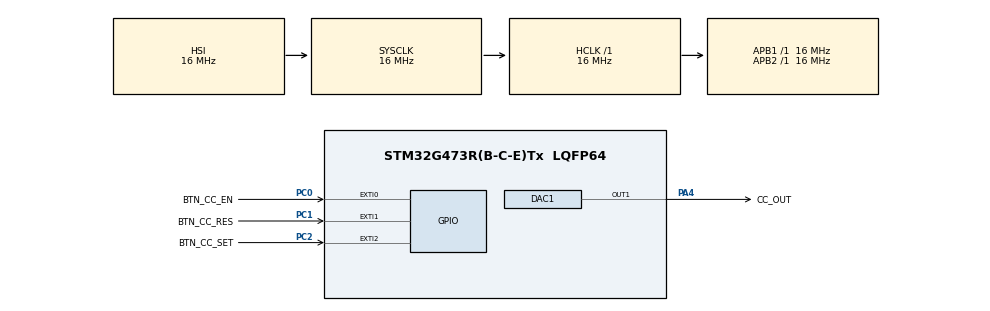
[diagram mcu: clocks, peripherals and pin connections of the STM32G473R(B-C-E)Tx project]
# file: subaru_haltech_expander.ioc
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FREERTOS.Queues01=ccStalkButtonEventQueue,10,16,1,Dynamic,NULL,NULL
FREERTOS.Tasks01=ccStalkTask,24,128,StartCCStalkTask,Default,NULL,Dynamic,NULL,NULL
FREERTOS.configUSE_NEWLIB_REENTRANT=1
Mcu.Family=STM32G4
Mcu.Name=STM32G473R(B-C-E)Tx
Mcu.Package=LQFP64
NVIC.EXTI0_IRQn=true\:5\:0\:false\:false\:true\:true\:true\:true\:true
NVIC.EXTI1_IRQn=true\:5\:0\:false\:false\:true\:true\:true\:true\:true
NVIC.EXTI2_IRQn=true\:5\:0\:false\:false\:true\:true\:true\:true\:true
NVIC.PriorityGroup=NVIC_PRIORITYGROUP_4
NVIC.TIM6_DAC_IRQn=true\:15\:0\:false\:false\:true\:false\:false\:true\:true
NVIC.TimeBase=TIM6_DAC_IRQn
NVIC.TimeBaseIP=TIM6
PA4.GPIO_Label=CC_OUT
PA4.Signal=COMP_DAC11_group
PC0.GPIO_Label=BTN_CC_EN
PC0.GPIO_PuPd=GPIO_PULLDOWN
PC0.Signal=GPXTI0
PC1.GPIO_Label=BTN_CC_RES
PC1.GPIO_PuPd=GPIO_PULLDOWN
PC1.Signal=GPXTI1
PC2.GPIO_Label=BTN_CC_SET
PC2.GPIO_PuPd=GPIO_PULLDOWN
PC2.Signal=GPXTI2
ProjectManager.HeapSize=0x200
ProjectManager.StackSize=0x400
ProjectManager.TargetToolchain=STM32CubeIDE
RCC.AHBFreq_Value=16000000
RCC.APB1Freq_Value=16000000
RCC.APB1TimFreq_Value=16000000
RCC.APB2Freq_Value=16000000
RCC.APB2TimFreq_Value=16000000
RCC.CortexFreq_Value=16000000
RCC.EXTERNAL_CLOCK_VALUE=12288000
RCC.HCLKFreq_Value=16000000
RCC.HSE_VALUE=8000000
RCC.HSI48_VALUE=48000000
RCC.HSI_VALUE=16000000
RCC.LSE_VALUE=32768
RCC.SYSCLKFreq_VALUE=16000000
RCC.USBFreq_Value=64000000
RCC.VCOOutputFreq_Value=128000000
SH.COMP_DAC11_group.0=DAC1_OUT1,DAC_OUT1
VP_FREERTOS_VS_CMSIS_V2.Mode=CMSIS_V2
VP_SYS_VS_DBSignals.Mode=DisableDeadBatterySignals
VP_SYS_VS_tim6.Mode=TIM6
board=custom

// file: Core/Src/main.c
/* USER CODE BEGIN Header */
/**
  ******************************************************************************
  * @file           : main.c
  * @brief          : Main program body
  ******************************************************************************
  * @attention
  *
  * Copyright (c) 2026 STMicroelectronics.
  * All rights reserved.
  *
  * This software is licensed under terms that can be found in the LICENSE file
  * in the root directory of this software component.
  * If no LICENSE file comes with this software, it is provided AS-IS.
  *
  ******************************************************************************
  */
/* USER CODE END Header */
#include "main.h"
#include "cmsis_os.h"

/* USER CODE BEGIN Includes */
#include "cruise_control_stalk.h"
/* USER CODE END Includes */

DAC_HandleTypeDef hdac1;

/* Definitions for ccStalkTask */
osThreadId_t ccStalkTaskHandle;
const osThreadAttr_t ccStalkTask_attributes = {
  .name = "ccStalkTask",
  .priority = (osPriority_t) osPriorityNormal,
  .stack_size = 128 * 4
};
/* Definitions for ccStalkButtonEventQueue */
osMessageQueueId_t ccStalkButtonEventQueueHandle;
const osMessageQueueAttr_t ccStalkButtonEventQueue_attributes = {
  .name = "ccStalkButtonEventQueue"
};

void SystemClock_Config(void);
static void MX_GPIO_Init(void);
static void MX_DAC1_Init(void);
void StartCCStalkTask(void *argument);

int main(void)
{

  /* MCU Configuration--------------------------------------------------------*/

  /* Reset of all peripherals, Initializes the Flash interface and the Systick. */
  HAL_Init();

  /* Configure the system clock */
  SystemClock_Config();

  /* Initialize all configured peripherals */
  MX_GPIO_Init();
  MX_DAC1_Init();

  /* Init scheduler */
  osKernelInitialize();

  /* Create the queue(s) */
  /* creation of ccStalkButtonEventQueue */
  ccStalkButtonEventQueueHandle = osMessageQueueNew (10, 16, &ccStalkButtonEventQueue_attributes);

  /* Create the thread(s) */
  /* creation of ccStalkTask */
  ccStalkTaskHandle = osThreadNew(StartCCStalkTask, NULL, &ccStalkTask_attributes);

  /* Start scheduler */
  osKernelStart();

  /* We should never get here as control is now taken by the scheduler */

  /* Infinite loop */
  while (1)
  {

  }
}

void SystemClock_Config(void)
{
  RCC_OscInitTypeDef RCC_OscInitStruct = {0};
  RCC_ClkInitTypeDef RCC_ClkInitStruct = {0};

  /** Configure the main internal regulator output voltage
  */
  HAL_PWREx_ControlVoltageScaling(PWR_REGULATOR_VOLTAGE_SCALE1);

  /** Initializes the RCC Oscillators according to the specified parameters
  * in the RCC_OscInitTypeDef structure.
  */
  RCC_OscInitStruct.OscillatorType = RCC_OSCILLATORTYPE_HSI;
  RCC_OscInitStruct.HSIState = RCC_HSI_ON;
  RCC_OscInitStruct.HSICalibrationValue = RCC_HSICALIBRATION_DEFAULT;
  RCC_OscInitStruct.PLL.PLLState = RCC_PLL_NONE;
  if (HAL_RCC_OscConfig(&RCC_OscInitStruct) != HAL_OK)
  {
    Error_Handler();
  }

  /** Initializes the CPU, AHB and APB buses clocks
  */
  RCC_ClkInitStruct.ClockType = RCC_CLOCKTYPE_HCLK|RCC_CLOCKTYPE_SYSCLK
                              |RCC_CLOCKTYPE_PCLK1|RCC_CLOCKTYPE_PCLK2;
  RCC_ClkInitStruct.SYSCLKSource = RCC_SYSCLKSOURCE_HSI;
  RCC_ClkInitStruct.AHBCLKDivider = RCC_SYSCLK_DIV1;
  RCC_ClkInitStruct.APB1CLKDivider = RCC_HCLK_DIV1;
  RCC_ClkInitStruct.APB2CLKDivider = RCC_HCLK_DIV1;

  if (HAL_RCC_ClockConfig(&RCC_ClkInitStruct, FLASH_LATENCY_0) != HAL_OK)
  {
    Error_Handler();
  }
}

static void MX_DAC1_Init(void)
{

  DAC_ChannelConfTypeDef sConfig = {0};

  /** DAC Initialization
  */
  hdac1.Instance = DAC1;
  if (HAL_DAC_Init(&hdac1) != HAL_OK)
  {
    Error_Handler();
  }

  /** DAC channel OUT1 config
  */
  sConfig.DAC_HighFrequency = DAC_HIGH_FREQUENCY_INTERFACE_MODE_AUTOMATIC;
  sConfig.DAC_DMADoubleDataMode = DISABLE;
  sConfig.DAC_SignedFormat = DISABLE;
  sConfig.DAC_SampleAndHold = DAC_SAMPLEANDHOLD_DISABLE;
  sConfig.DAC_Trigger = DAC_TRIGGER_NONE;
  sConfig.DAC_Trigger2 = DAC_TRIGGER_NONE;
  sConfig.DAC_OutputBuffer = DAC_OUTPUTBUFFER_ENABLE;
  sConfig.DAC_ConnectOnChipPeripheral = DAC_CHIPCONNECT_EXTERNAL;
  sConfig.DAC_UserTrimming = DAC_TRIMMING_FACTORY;
  if (HAL_DAC_ConfigChannel(&hdac1, &sConfig, DAC_CHANNEL_1) != HAL_OK)
  {
    Error_Handler();
  }

}

static void MX_GPIO_Init(void)
{
  GPIO_InitTypeDef GPIO_InitStruct = {0};

  /* GPIO Ports Clock Enable */
  __HAL_RCC_GPIOC_CLK_ENABLE();
  __HAL_RCC_GPIOA_CLK_ENABLE();

  /*Configure GPIO pins : BTN_CC_EN_Pin BTN_CC_RES_Pin BTN_CC_SET_Pin */
  GPIO_InitStruct.Pin = BTN_CC_EN_Pin|BTN_CC_RES_Pin|BTN_CC_SET_Pin;
  GPIO_InitStruct.Mode = GPIO_MODE_IT_RISING;
  GPIO_InitStruct.Pull = GPIO_PULLDOWN;
  HAL_GPIO_Init(GPIOC, &GPIO_InitStruct);

  /* EXTI interrupt init*/
  HAL_NVIC_SetPriority(EXTI0_IRQn, 5, 0);
  HAL_NVIC_EnableIRQ(EXTI0_IRQn);

  HAL_NVIC_SetPriority(EXTI1_IRQn, 5, 0);
  HAL_NVIC_EnableIRQ(EXTI1_IRQn);

  HAL_NVIC_SetPriority(EXTI2_IRQn, 5, 0);
  HAL_NVIC_EnableIRQ(EXTI2_IRQn);

}

void StartCCStalkTask(void *argument)
{
  /* USER CODE BEGIN 5 */
	CCStalkInit();

	TickType_t last_wake_time = xTaskGetTickCount();
	const TickType_t poll_period = pdMS_TO_TICKS(10); // 10ms
	ButtonMessage_t msg;

	for(;;)
	{
		// Process buttons
		CCStalkProcessButtons();

		// Check for events (non-blocking)
		if(osMessageQueueGet(ccStalkButtonEventQueueHandle, &msg, NULL, 0) == osOK)
		{
			// For now, just toggle an LED or set a breakpoint here
			// You can see msg.button and msg.event in the debugger
			__NOP();
		}

		vTaskDelayUntil(&last_wake_time, poll_period);
	}
  /* USER CODE END 5 */
}

void HAL_TIM_PeriodElapsedCallback(TIM_HandleTypeDef *htim)
{
  if (htim->Instance == TIM6)
  {
    HAL_IncTick();
  }
}

void Error_Handler(void)
{
  __disable_irq();
  while (1)
  {
  }
}
